# SPC1169 register map
File version: 2022071043481212
CPU: cm4 r1p0, little endian, no MPU, FPU, 4 interrupt priority bits
Registers are 32-bit, read-write, reset 0x0 unless marked. A register's access mark holds for its fields unless they carry their own. Offsets are from the block's base; [hi:lo] are bit positions; {n}, {i} and the like mark numbered series; 'fields as' and 'values as' point back to an identical list.

## PWM0 (part 1 of 2)
Base 0x40002000
Same registers: PWM1 0x40002100, PWM2 0x40002200, PWM3 0x40002300
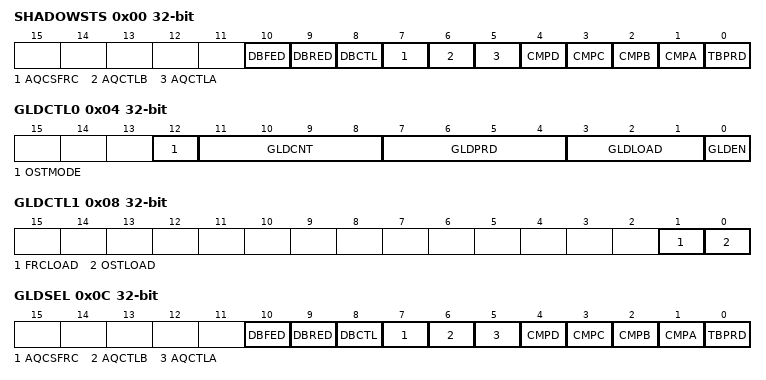
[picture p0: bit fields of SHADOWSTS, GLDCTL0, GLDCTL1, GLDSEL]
0x00 SHADOWSTS ro — Shadow Status Register
  [10] DBFED — DBFED shadow status
    0=EMPTY (A load from DBFED to DBFEDA clears this bit); 1=FULL (Write to DBFED set this bit and overwrite current value in DBFED)
  [9] DBRED — DBRED shadow status
    0=EMPTY (A load from DBRED to DBREDA clears this bit); 1=FULL (Write to DBRED set this bit and overwrite current value in DBRED)
  [8] DBCTL — DBCTL shadow status
    0=EMPTY (A load from DBCTL to DBCTLA clears this bit); 1=FULL (Write to DBCTL set this bit and overwrite current value in DBCTL)
  [7] AQCSFRC — AQCSFRC shadow status
    0=EMPTY (A load from AQCSFRC to AQCSFRCA clears this bit); 1=FULL (Write to AQCSFRC set this bit and overwrite current value in AQCSFRC)
  [6] AQCTLB — AQCTLB shadow status
    0=EMPTY (A load from AQCTLB to AQCTLBA clears this bit); 1=FULL (Write to AQCTLB set this bit and overwrite current value in AQCTLB)
  [5] AQCTLA — AQCTLA shadow status
    0=EMPTY (A load from AQCTLA to AQCTLAA clears this bit); 1=FULL (Write to AQCTLA set this bit and overwrite current value in AQCTLA)
  [4] CMPD — CMPD shadow status
    0=EMPTY (A load from CMPD to CMPDA clears this bit); 1=FULL (Write to CMPD set this bit and overwrite current value in CMPD)
  [3] CMPC — CMPC shadow status
    0=EMPTY (A load from CMPC to CMPCA clears this bit); 1=FULL (Write to CMPC set this bit and overwrite current value in CMPC)
  [2] CMPB — CMPB shadow status
    0=EMPTY (A load from CMPB to CMPBA clears this bit); 1=FULL (Write to CMPB set this bit and overwrite current value in CMPB)
  [1] CMPA — CMPA shadow status
    0=EMPTY (A load from CMPA to CMPAA clears this bit); 1=FULL (Write to CMPA set this bit and overwrite current value in CMPA)
  [0] TBPRD — TBPRD shadow status
    0=EMPTY (A load from TBPRD to TBPRDA clears this bit); 1=FULL (Write to TBPRD set this bit and overwrite current value in TBPRD)
0x04 GLDCTL0 — Global Shadow to Active Load Control Register 0
  [12] OSTMODE — One-shot global load mode
    0=CONTINUOUS_MODE (Global strobe is continuously controlled by GLDPRD and GLDCNT); 1=ONE_SHOT_MODE (Global strobe is blocked until GLDCTL1[OSTLOAD] is written with 1)
  [11:8] GLDCNT ro — Global shadow to active load strobe counter. It indicates how many selected global load events have occurred
  [7:4] GLDPRD — Global shadow to active load strobe period. No global load pulse will be generated if GLDPRD=0. Otherwise, the global load pulse is generated when new event comes upon GLDCNT=GLDPRD-1. In other words, the load pulse is generated every GLDPRD events. It has no effect if OSTMODE=1
  [3:1] GLDLOAD — Global shadow to active load mode
    0=LOAD_ON_ZERO (Load from shadow to active on TBCNT=0); 1=LOAD_ON_PERIOD (Load from shadow to active on TBCNT=TBPRD); 2=LOAD_ON_ZERO_PERIOD (Load from shadow to active on TBCNT=0 or TBCNT=TBPRD); 3=LOAD_ON_SYNC (Load from shadow to active on SYNC event); 4=LOAD_ON_SYNC_ZERO (Load from shadow to active on SYNC event or TBCNT=0); 5=LOAD_ON_SYNC_PERIOD (Load from shadow to active on SYNC event or TBCNT=TBPRD); 6=LOAD_ON_SYNC_ZERO_PERIOD (Load from shadow to active on SYNC event, TBCNT=0 or TBCNT=TBPRD); 7=LOAD_ON_FORCE (Load from shadow to active on software by writing 1 to GLDCTL1[FRCLOAD])
  [0] GLDEN — Global shadow to active load enable
    0=DISABLE (Shadow to active load is defined per register regardless of GLDSEL. i.e. CMPA load is always controlled by CMPCTL[CMPALOAD]); 1=ENABLE (Shadow to active load is globally controlled)
0x08 GLDCTL1 — Global Shadow to Active Load Control Register 1
  [1] FRCLOAD — Global force shadow to active load
    0=NO_EFFECT (Write 0 has no effect and always reads back 0); 1=FORCE (Write 1 generates global load event to the event counter)
  [0] OSTLOAD — Start the one-shot load pending
    0=NO_EFFECT (Write 0 has no effect. Read 0 indicates there is no pending one-shot load); 1=PENDING (Write 1 initialize a one-shot load pending. Upon event defined by GLDCTL[GLDLOAD], the global load happens and this bit is self-cleared to 0.)
0x0C GLDSEL — Global Shadow to Active Load Select Register
  [10] DBFED — DBFED global shadow to active load select
    0=LOCAL (Shadow to active load is controlled by DBCTL[DBFEDLOAD]); 1=GLOBAL (Shadow to active load is controlled by GLDCTL)
  [9] DBRED — DBRED global shadow to active load select
    0=LOCAL (Shadow to active load is controlled by DBCTL[DBREDLOAD]); 1=GLOBAL (Shadow to active load is controlled by GLDCTL)
  [8] DBCTL — DBCTL global shadow to active load select
    0=LOCAL (Shadow to active load is controlled by DBCTL[DBCTLLOAD]); 1=GLOBAL (Shadow to active load is controlled by GLDCTL)
  [7] AQCSFRC — AQCSFRC global shadow to active load select
    0=LOCAL (Shadow to active load is controlled by AQCTL[AQCSFRCLOAD]); 1=GLOBAL (Shadow to active load is controlled by GLDCTL)
  [6] AQCTLB — AQCTLB global shadow to active load select
    0=LOCAL (Shadow to active load is controlled by AQCTL[AQCTLBLOAD]); 1=GLOBAL (Shadow to active load is controlled by GLDCTL)
  [5] AQCTLA — AQCTLA global shadow to active load select
    0=LOCAL (Shadow to active load is controlled by AQCTL[AQCTLALOAD]); 1=GLOBAL (Shadow to active load is controlled by GLDCTL)
  [4] CMPD — CMPD global shadow to active load select
    0=LOCAL (Shadow to active load is controlled by CMPCTL[CMPDLOAD]); 1=GLOBAL (Shadow to active load is controlled by GLDCTL)
  [3] CMPC — CMPC global shadow to active load select
    0=LOCAL (Shadow to active load is controlled by CMPCTL[CMPCLOAD]); 1=GLOBAL (Shadow to active load is controlled by GLDCTL)
  [2] CMPB — CMPB global shadow to active load select
    0=LOCAL (Shadow to active load is controlled by CMPCTL[CMPBLOAD]); 1=GLOBAL (Shadow to active load is controlled by GLDCTL)
  [1] CMPA — CMPA global shadow to active load select
    0=LOCAL (Shadow to active load is controlled by CMPCTL[CMPALOAD]); 1=GLOBAL (Shadow to active load is controlled by GLDCTL)
  [0] TBPRD — TBPRD global shadow to active load select
    0=LOCAL (Shadow to active load is controlled by TBCTL[TBPRDLOAD]); 1=GLOBAL (Shadow to active load is controlled by GLDCTL)
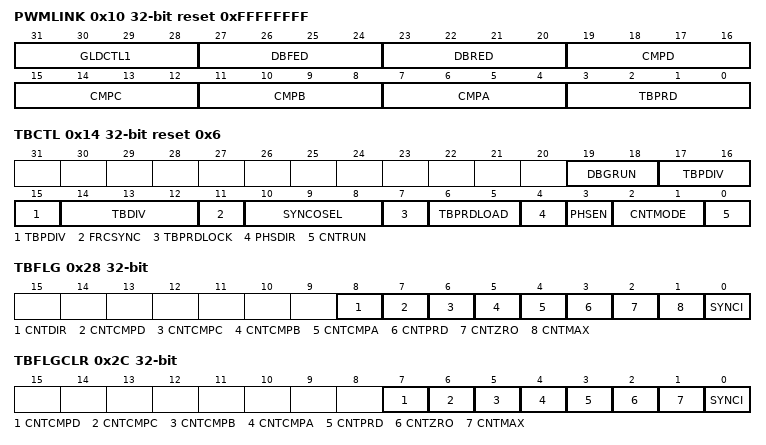
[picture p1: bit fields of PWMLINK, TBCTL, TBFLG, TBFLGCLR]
0x10 PWMLINK reset 0xFFFFFFFF — PWM Link Control Register
  [all] fields
    {v}=LINK_PWM{v} (Select PWM{v}) (v=0..3); 15=LINK_NONE (No PWM selected)
  [31:28] GLDCTL1 — Write to the GLDCTL1 of PWM selected by PWMLINK[GLDCTL1] results in simultaneous write to GLDCTL1 of current PWM module
  [27:24] DBFED — Write to the DBFED of PWM selected by PWMLINK[DBFED] results in simultaneous write to DBFED of current PWM module
  [23:20] DBRED — Write to the DBRED of PWM selected by PWMLINK[DBRED] results in simultaneous write to DBRED of current PWM module
  [19:16] CMPD — Write to the CMPD of PWM selected by PWMLINK[CMPD] results in simultaneous write to CMPD of current PWM module
  [15:12] CMPC — Write to the CMPC of PWM selected by PWMLINK[CMPC] results in simultaneous write to CMPC of current PWM module
  [11:8] CMPB — Write to the CMPB of PWM selected by PWMLINK[CMPB] results in simultaneous write to CMPB of current PWM module
  [7:4] CMPA — Write to the CMPA of PWM selected by PWMLINK[CMPA] results in simultaneous write to CMPA of current PWM module
  [3:0] TBPRD — Write to the TBPRD of PWM selected by PWMLINK[TBPRD] results in simultaneous write to TBPRD of current PWM module
0x14 TBCTL reset 0x6 — Time-Base Control Register
  [19:18] DBGRUN — PWM counter behaviour when CPU is halted . Note: Debug operation and CPU fault exceptions both can cause CPU halted.
    0=STOP_AFTER_COUNTING (Stop after the next time-base counter increment or decrement); 1=STOP_AFTER_CYCLE (Stop when TBCNT completes a whole cycle (TBCNT=TBPRD for up-count mode and TBCNT=0 for other modes)); 2=KEEP_RUN (Counter keep running when CPU is halted)
  [17:15] TBPDIV — TBCLK pre-dividing ratio from PWM clock input. Overall dividing ratio is 2^TBPDIV * (TBDIV+1)
    0=/1 (default on reset); 1=2; 2=4; 3=8; 4=16; 5=32; 6=64; 7=128
  [14:12] TBDIV — TBCLK dividing ratio from pre-divider output. Overall dividing ratio is 2^TBPDIV * (TBDIV+1)
    0=/1 (default on reset); {v}={v+1} (v=1..7)
  [11] FRCSYNC — Software forced synchronization. This event is ORed with SYNCI input and is valid only when SYNCOSEL=000
    0=NO_EFFECT (Write 0 has no effect and always reads back 0); 1=FORCE (Write 1 forces a one-time synchronization pulse. This bit is self-cleared to 0 and not affected by PWMREGKEY protection)
  [10:8] SYNCOSEL — Synchronization output select
    0=SYNCI_AND_FRCSYNC (SYNCI and the software forced sync); 1=TBCNT_EQU_ZERO (TBCNT=0 event); 2=TBCNT_EQU_TBPRD (TBCNT=TBPRD event); 3=TBCNT_EQU_CMPA (TBCNT=CMPA event); 4=TBCNT_EQU_CMPB (TBCNT=CMPB event); 5=TBCNT_EQU_CMPC (TBCNT=CMPC event); 6=TBCNT_EQU_CMPD (TBCNT=CMPD event); 7=DISABLE (Disable SYNCO)
  [7] TBPRDLOCK — TBPRD active value lock
    0=UNLOCK (Active value in TBPRDA is updated according to TBCTL[TBPRDLOAD]); 1=LOCK (Active value in TBPRDA will not change)
  [6:5] TBPRDLOAD — TBPRD active value load mode. It has no effect when TBCTL[TBPRDLOCK]=1
    0=LOAD_ON_ZERO (Load TBPRD into TBPRDA on TBCNT=0); 1=LOAD_ON_SYNC (Load TBPRD into TBPRDA on SYNC event); 2=LOAD_ON_SYNC_ZERO (Load TBPRD into TBPRDA on SYNC event or TBCNT=0); 3=LOAD_IMMEDIATE (Write TBPRD will immediately change the active value in TBPRDA)
  [4] PHSDIR — Phase direction. It is valid only when TBCNT is in up-down-count mode (CNTMODE=10)
    0=COUNT_DOWN_AFTER_SYNC (Count down after synchronization event); 1=COUNT_UP_AFTER_SYNC (Count up after synchronization event)
  [3] PHSEN — Phase register enable
    0=DISABLE (Do not load time-base counter (TBCNT) from time-base phase register (TBPHS)); 1=ENABLE (Load TBCNT from TBPHS when synchronization event occurs (SYNCI input, software synchronization or digital compare sync event))
  [2:1] CNTMODE — Counter mode
    0=COUNT_DOWN (Down-count); 1=COUNT_UP (Up-count); 2=COUNT_UP_DOWN (Up-down-count); 3=COUNT_FREEZE (Stop and freeze (default on reset))
  [0] CNTRUN — Counter run/stop control
    0=COUNT_STOP (Counter stop); 1=COUNT_RUN (Counter free-running)
0x18 TBPRD — Time-Base Period Register
  [15:0] VAL — Time-base counter period
0x1C TBPRDA ro — Time-Base Period Active Register
  [15:0] VAL — Time-base counter active period. When TBCTL[PRDLOAD]=0x3, write to TBPRD directly affects this register. Otherwise, the value is loaded from TBPRD upon the events defined in TBCTL[PRDLOAD].
0x20 TBPHS — Time-Base Phase Register
  [15:0] VAL — Time-base counter phase when synchronization event occurs. TBCTL[PHSEN]=0: The synchronization event is ignored and TBCNT keeps its value. TBCTL[PHSEN]=1: Time-base counter (TBCNT) will be loaded with TBPHS when synchronization event occurs.
0x24 TBCNT — Time-Base Counter Register
  [15:0] VAL — Current value of the time-base counter
0x28 TBFLG ro — Time-Base Status Register
  [8] CNTDIR — Time-base counter direction status
    0=COUNTING_DOWN (Time-base counter is currently counting down); 1=COUNTING_UP (Time-base counter is currently counting up)
  [7] CNTCMPD — Time-base counter reaching CMPD latched status
    0=NOT_REACHED (TBCNT never reaches CMPD); 1=REACHED (TBCNT reached CMPD)
  [6] CNTCMPC — Time-base counter reaching CMPC latched status
    0=NOT_REACHED (TBCNT never reaches CMPC); 1=REACHED (TBCNT reached CMPC)
  [5] CNTCMPB — Time-base counter reaching CMPB latched status
    0=NOT_REACHED (TBCNT never reaches CMPB); 1=REACHED (TBCNT reached CMPB)
  [4] CNTCMPA — Time-base counter reaching CMPA latched status
    0=NOT_REACHED (TBCNTnever reaches CMPA); 1=REACHED (TBCNT reached CMPA)
  [3] CNTPRD — Time-base counter reaching period latched status
    0=NOT_REACHED (TBCNT never reaches TBPRD); 1=REACHED (TBCNT reached TBPRD)
  [2] CNTZRO — Time-base counter reaching zero latched status
    0=NOT_REACHED (TBCNT never reaches 0x0); 1=REACHED (TBCNT reached 0x0)
  [1] CNTMAX — Time-base counter reaching max latched status
    0=NOT_REACHED (TBCNT never reaches 0xFFFF); 1=REACHED (TBCNT reached 0xFFFF)
  [0] SYNCI — Input synchronization latched status
    0=NO_EVENT (No input synchronization event has occurred); 1=EVENT_OCCUR (An input synchronization event has occurred)
0x2C TBFLGCLR — Time-Base Status Clear Register
  [7] CNTCMPD — Time-base counter reaching CMPD latched status clear
    0=NO_EFFECT (Write 0 has no effect and always reads back 0); 1=CLEAR (Write 1 cleares the TZFLG.CNTCMPD. This bit is self-cleared to 0)
  [6] CNTCMPC — Time-base counter reaching CMPC latched status clear
    0=NO_EFFECT (Write 0 has no effect and always reads back 0); 1=CLEAR (Write 1 cleares the TZFLG.CNTCMPC. This bit is self-cleared to 0)
  [5] CNTCMPB — Time-base counter reaching CMPB latched status clear
    0=NO_EFFECT (Write 0 has no effect and always reads back 0); 1=CLEAR (Write 1 cleares the TZFLG.CNTCMPB. This bit is self-cleared to 0)
  [4] CNTCMPA — Time-base counter reaching CMPA latched status clear
    0=NO_EFFECT (Write 0 has no effect and always reads back 0); 1=CLEAR (Write 1 cleares the TZFLG.CNTCMPA. This bit is self-cleared to 0)
  [3] CNTPRD — Time-base counter reaching period latched status clear
    0=NO_EFFECT (Write 0 has no effect and always reads back 0); 1=CLEAR (Write 1 cleares the TZFLG.CNTPRD. This bit is self-cleared to 0)
  [2] CNTZRO — Time-base counter reaching zero latched status clear
    0=NO_EFFECT (Write 0 has no effect and always reads back 0); 1=CLEAR (Write 1 cleares the TZFLG.CNTZRO. This bit is self-cleared to 0)
  [1] CNTMAX — Time-base counter reaching max latched status clear
    0=NO_EFFECT (Write 0 has no effect and always reads back 0); 1=CLEAR (Write 1 cleares the TZFLG.CNTMAX. This bit is self-cleared to 0)
  [0] SYNCI — Input synchronization latched status clear
    0=NO_EFFECT (Write 0 has no effect and always reads back 0); 1=CLEAR (Write 1 cleares the TZFLG.SYNCI. This bit is self-cleared to 0)
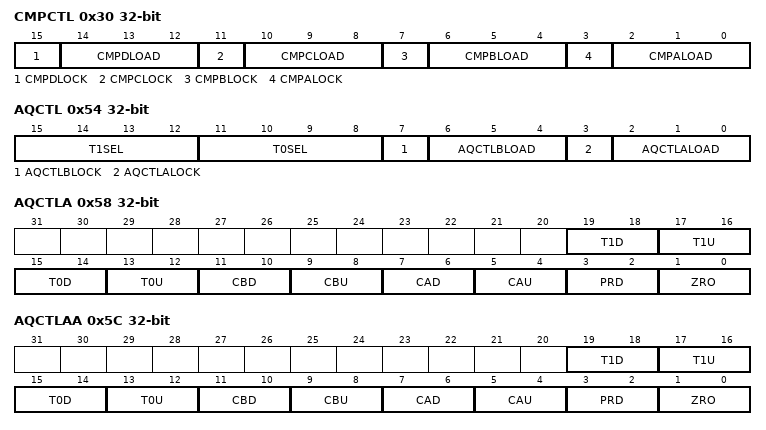
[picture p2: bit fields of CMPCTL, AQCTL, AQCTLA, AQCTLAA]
0x30 CMPCTL — Counter-Compare Control Register
  [15] CMPDLOCK — CMPD active value lock
    0=UNLOCK (Active value in CMPDA is updated according to CMPCTL.CMPDLOAD); 1=LOCK (Active value in CMPDA will not change)
  [14:12] CMPDLOAD — CMPD active value load mode. It has no effect when CMPCTL[CMPDLOCK]=1
    0=LOAD_ON_ZERO (Load CMPD into CMPDA on TBCNT=0); 1=LOAD_ON_PERIOD (Load CMPD into CMPDA on TBCNT=TBPRD); 2=LOAD_ON_ZERO_PERIOD (Load CMPD into CMPDA on TBCNT=0 or TBCNT=TBPRD); 3=LOAD_ON_SYNC (Load CMPD into CMPDA on SYNC event); 4=LOAD_ON_SYNC_ZERO (Load CMPD into CMPDA on SYNC event or TBCNT=0); 5=LOAD_ON_SYNC_PERIOD (Load CMPD into CMPDA on SYNC event or TBCNT=TBPRD); 6=LOAD_ON_SYNC_ZERO_PERIOD (Load CMPD into CMPDA on SYNC event, TBCNT=0 or TBCNT=TBPRD); 7=LOAD_IMMEDIATE (Write CMPD will immediately change the active value in CMPDA)
  [11] CMPCLOCK — CMPC active value lock
    0=UNLOCK (Active value in CMPCA is updated according to CMPCTL.CMPCLOAD); 1=LOCK (Active value in CMPCA will not change)
  [10:8] CMPCLOAD — CMPC active value load mode. It has no effect when CMPCTL[CMPCLOCK]=1
    0=LOAD_ON_ZERO (Load CMPC into CMPCA on TBCNT=0); 1=LOAD_ON_PERIOD (Load CMPC into CMPCA on TBCNT=TBPRD); 2=LOAD_ON_ZERO_PERIOD (Load CMPC into CMPCA on TBCNT=0 or TBCNT=TBPRD); 3=LOAD_ON_SYNC (Load CMPC into CMPCA on SYNC event); 4=LOAD_ON_SYNC_ZERO (Load CMPC into CMPCA on SYNC event or TBCNT=0); 5=LOAD_ON_SYNC_PERIOD (Load CMPC into CMPCA on SYNC event or TBCNT=TBPRD); 6=LOAD_ON_SYNC_ZERO_PERIOD (Load CMPC into CMPCA on SYNC event, TBCNT=0 or TBCNT=TBPRD); 7=LOAD_IMMEDIATE (Write CMPC will immediately change the active value in CMPCA)
  [7] CMPBLOCK — CMPB active value lock
    0=UNLOCK (Active value in CMPBA is updated according to CMPBTL.CMPBLOAD); 1=LOCK (Active value in CMPBA will not change)
  [6:4] CMPBLOAD — CMPB active value load mode. It has no effect when CMPBTL[CMPBLOCK]=1
    0=LOAD_ON_ZERO (Load CMPB into CMPBA on TBCNT=0); 1=LOAD_ON_PERIOD (Load CMPB into CMPBA on TBCNT=TBPRD); 2=LOAD_ON_ZERO_PERIOD (Load CMPB into CMPBA on TBCNT=0 or TBCNT=TBPRD); 3=LOAD_ON_SYNC (Load CMPB into CMPBA on SYNC event); 4=LOAD_ON_SYNC_ZERO (Load CMPB into CMPBA on SYNC event or TBCNT=0); 5=LOAD_ON_SYNC_PERIOD (Load CMPB into CMPBA on SYNC event or TBCNT=TBPRD); 6=LOAD_ON_SYNC_ZERO_PERIOD (Load CMPB into CMPBA on SYNC event, TBCNT=0 or TBCNT=TBPRD); 7=LOAD_IMMEDIATE (Write CMPB will immediately change the active value in CMPBA)
  [3] CMPALOCK — CMPA active value lock
    0=UNLOCK (Active value in CMPAA is updated according to CMPATL.CMPALOAD); 1=LOCK (Active value in CMPAA will not change)
  [2:0] CMPALOAD — CMPA active value load mode. It has no effect when CMPATL[CMPALOCK]=1
    0=LOAD_ON_ZERO (Load CMPA into CMPAA on TBCNT=0); 1=LOAD_ON_PERIOD (Load CMPA into CMPAA on TBCNT=TBPRD); 2=LOAD_ON_ZERO_PERIOD (Load CMPA into CMPAA on TBCNT=0 or TBCNT=TBPRD); 3=LOAD_ON_SYNC (Load CMPA into CMPAA on SYNC event); 4=LOAD_ON_SYNC_ZERO (Load CMPA into CMPAA on SYNC event or TBCNT=0); 5=LOAD_ON_SYNC_PERIOD (Load CMPA into CMPAA on SYNC event or TBCNT=TBPRD); 6=LOAD_ON_SYNC_ZERO_PERIOD (Load CMPA into CMPAA on SYNC event, TBCNT=0 or TBCNT=TBPRD); 7=LOAD_IMMEDIATE (Write CMPA will immediately change the active value in CMPAA)
0x34 CMPA — Counter-Compare A Threshold Register
  [15:0] VAL — Comparator A threshold
0x38 CMPAA ro — Counter-Compare A Threshold Active Register
  [15:0] VAL — Comparator A threshold active value. A TBCNT=CMPA event will be generated while TBCNT is equal to the threshold value
0x3C CMPB — Counter-Compare B Threshold Register
  [15:0] VAL — Comparator B threshold
0x40 CMPBA ro — Counter-Compare B Threshold Active Register
  [15:0] VAL — Comparator B threshold active value. A TBCNT=CMPB event will be generated while TBCNT is equal to the threshold value
0x44 CMPC — Counter-Compare C Threshold Register
  [15:0] VAL — Comparator C threshold
0x48 CMPCA ro — Counter-Compare C Threshold Active Register
  [15:0] VAL — Comparator C threshold active value. A TBCNT=CMPC event will be generated while TBCNT is equal to the threshold value
0x4C CMPD — Counter-Compare D Threshold Register
  [15:0] VAL — Comparator D threshold
0x50 CMPDA ro — Counter-Compare D Threshold Active Register
  [15:0] VAL — Comparator D threshold active value. A TBCNT=CMPD event will be generated while TBCNT is equal to the threshold value
0x54 AQCTL — Action-Qualifier Control Register
  [15:12] T1SEL — T1 event source select
    0=DCAEVT0; 1=DCAEVT1; 2=DCBEVT0; 3=DCBEVT1; {v}=TZ{v-4} (v=4..8); 9=SYNCI
  [11:8] T0SEL — T0 event source select
    values as T1SEL
  [7] AQCTLBLOCK — AQCTLB active value lock
    0=UNLOCK (Active value in AQCTLBA is updated according to AQCTL.AQCTLBLOAD); 1=LOCK (Active value in AQCTLBA will not change)
  [6:4] AQCTLBLOAD — AQCTLB active value load mode. It has no effect when AQCTL[AQCTLBLOCK]=1
    0=LOAD_ON_ZERO (Load AQCTLB into AQCTLBA on TBCNT=0); 1=LOAD_ON_PERIOD (Load AQCTLB into AQCTLBA on TBCNT=TBPRD); 2=LOAD_ON_ZERO_PERIOD (Load AQCTLB into AQCTLBA on TBCNT=0 or TBCNT=TBPRD); 3=LOAD_ON_SYNC (Load AQCTLB into AQCTLBA on SYNC event); 4=LOAD_ON_SYNC_ZERO (Load AQCTLB into AQCTLBA on SYNC event or TBCNT=0); 5=LOAD_ON_SYNC_PERIOD (Load AQCTLB into AQCTLBA on SYNC event or TBCNT=TBPRD); 6=LOAD_ON_SYNC_ZERO_PERIOD (Load AQCTLB into AQCTLBA on SYNC event, TBCNT=0 or TBCNT=TBPRD); 7=LOAD_IMMEDIATE (Write AQCTLB immediately change the active value in AQCTLBA)
  [3] AQCTLALOCK — AQCTLA active value lock
    0=UNLOCK (Active value in AQCTLAA is updated according to AQCTL[AQCTLALOAD]); 1=LOCK (Active value in AQCTLAA will not change)
  [2:0] AQCTLALOAD — AQCTLA active value load mode. It has no effect when AQCTL[AQCTLALOCK]=1
    0=LOAD_ON_ZERO (Load AQCTLA into AQCTLAA on TBCNT=0); 1=LOAD_ON_PERIOD (Load AQCTLA into AQCTLAA on TBCNT=TBPRD); 2=LOAD_ON_ZERO_PERIOD (Load AQCTLA into AQCTLAA on TBCNT=0 or TBCNT=TBPRD); 3=LOAD_ON_SYNC (Load AQCTLA into AQCTLAA on SYNC event); 4=LOAD_ON_SYNC_ZERO (Load AQCTLA into AQCTLAA on SYNC event or TBCNT=0); 5=LOAD_ON_SYNC_PERIOD (Load AQCTLA into AQCTLAA on SYNC event or TBCNT=TBPRD); 6=LOAD_ON_SYNC_ZERO_PERIOD (Load AQCTLA into AQCTLAA on SYNC event, TBCNT=0 or TBCNT=TBPRD); 7=LOAD_IMMEDIATE (Write AQCTLA immediately change the active value in AQCTLAA)
0x58 AQCTLA — Action-Qualifier Output A Control Register
  [all] fields
    0=DO_NOTHING (Do nothing (action disabled)); 1=SET_LOW (Clear (force PWM output A to low)); 2=SET_HIGH (Set (force PWM output A to high)); 3=TOGGLE (Toggle (invert current PWM output A status))
  [19:18] T1D — Action on output A when T1 event and TBCNT is counting down
  [17:16] T1U — Action on output A when T1 event and TBCNT is counting up
  [15:14] T0D — Action on output A when T0 event and TBCNT is counting down
  [13:12] T0U — Action on output A when T0 event and TBCNT is counting up
  [11:10] CBD — Action on output A when TBCNT=CMPB and TBCNT is counting down
  [9:8] CBU — Action on output A when TBCNT=CMPB and TBCNT is counting up
  [7:6] CAD — Action on output A when TBCNT=CMPA and TBCNT is counting down
  [5:4] CAU — Action on output A when TBCNT=CMPA and TBCNT is counting up
  [3:2] PRD — Action on output A when TBCNT=TBPRD
  [1:0] ZRO — Action on output A when TBCNT=Zero
0x5C AQCTLAA ro — Action-Qualifier Output A Control Active Register
  fields as AQCTLA
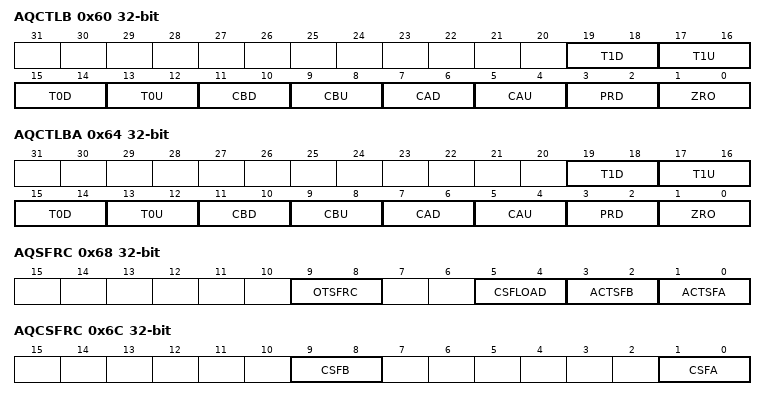
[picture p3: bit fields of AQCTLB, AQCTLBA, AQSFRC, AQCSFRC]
0x60 AQCTLB — Action-Qualifier Output B Control Register
  [all] fields
    0=DO_NOTHING (Do nothing (action disabled)); 1=SET_LOW (Clear (force PWM output B to low)); 2=SET_HIGH (Set (force PWM output B to high)); 3=TOGGLE (Toggle (invert current PWM output B status))
  [19:18] T1D — Action on output B when T1 event and TBCNT is counting down
  [17:16] T1U — Action on output B when T1 event and TBCNT is counting up
  [15:14] T0D — Action on output B when T0 event and TBCNT is counting down
  [13:12] T0U — Action on output B when T0 event and TBCNT is counting up
  [11:10] CBD — Action on output B when TBCNT=CMPA and TBCNT is counting down
  [9:8] CBU — Action on output B when TBCNT=CMPB and TBCNT is counting up
  [7:6] CAD — Action on output B when TBCNT=CMPA and TBCNT is counting down
  [5:4] CAU — Action on output B when TBCNT=CMPA and TBCNT is counting up
  [3:2] PRD — Action on output B when TBCNT=TBPRD
  [1:0] ZRO — Action on output B when TBCNT=Zero
0x64 AQCTLBA ro — Action-Qualifier Output B Control Active Register
  fields as AQCTLB
0x68 AQSFRC — Action-Qualifier Software Force Register
  [9:8] OTSFRC — One-time software forced event on output
    0=NO_EFFECT (Write a 0 has no effect and always reads back 0); 1=FORCE_A; 2=FORCE_B; 3=FORCE_A_AND_B (Write a 1 initialize a one-cycle force pulse. This bit is self-cleared to 0)
  [5:4] CSFLOAD — Options to load continuous software force register (AQCSFRC) active value from shadow register
    0=LOAD_ON_ZERO (Load from AQCSFRC into AQCSFRCA on TBCNT=0); 1=LOAD_ON_PERIOD (Load from AQCSFRC into AQCSFRCA on TBCNT=TBPRD); 2=LOAD_ON_ZERO_PERIOD (Load from AQCSFRC into AQCSFRCA on TBCNT=Zero or TBCNT=TBPRD); 3=LOAD_IMMEDIATE (Write AQCSFRC immediately change the active value in AQCSFRCA)
  [3:2] ACTSFB — Action when one-time software force B is invoked
    0=DO_NOTHING (Do nothing (action disabled)); 1=SET_LOW (Clear (force PWM output B to low); 2=SET_HIGH (Set (force PWM output B to high); 3=TOGGLE (Toggle (invert current PWM AQ output B status))
  [1:0] ACTSFA — Action when one-time software force A is invoked
    0=DO_NOTHING (Do nothing (action disabled)); 1=SET_LOW (Clear (force PWM output A to low); 2=SET_HIGH (Set (force PWM output A to high); 3=TOGGLE (Toggle (invert current PWM AQ output A status))
0x6C AQCSFRC — Action-Qualifier Continuous Software Force Register
  [9:8] CSFB — Continuous software force on output B
    0=DISABLE (Forcing disabled); 1=FORCE_CONTINUOUS_LOW (Force a continuous low on output B); 2=FORCE_CONTINUOUS_HIGH (Force a continuous high on output B); 3=NO_EFFECT (Invalid option)
  [1:0] CSFA — Continuous software force on output A
    0=DISABLE (Forcing disabled); 1=FORCE_CONTINUOUS_LOW (Force a continuous low on output A); 2=FORCE_CONTINUOUS_HIGH (Force a continuous high on output A); 3=NO_EFFECT (Invalid option)
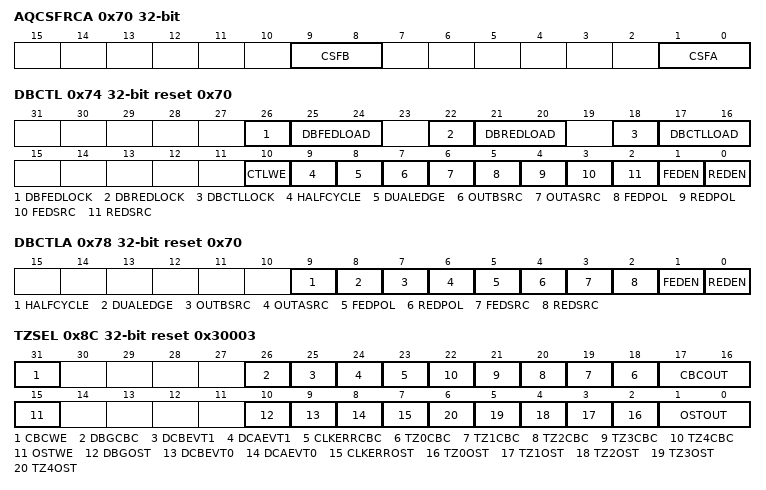
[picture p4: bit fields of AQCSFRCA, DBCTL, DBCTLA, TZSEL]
0x70 AQCSFRCA ro — Action-Qualifier Continuous Software Force Active Register
  fields as AQCSFRC
0x74 DBCTL reset 0x70 — Dead-Band Generator Control Register
  [26] DBFEDLOCK — DBFED active value lock
    0=UNLOCK (Active value in DBFEDA is updated according to DBCTL[DBFEDLOAD]); 1=LOCK (Active value in DBFEDA will not change)
  [25:24] DBFEDLOAD — DBFED active value load mode. It has no effect when DBCTL[DBFEDLOCK]=1
    0=LOAD_ON_ZERO (Load DBFED into DBFEDA on TBCNT=0); 1=LOAD_ON_PERIOD (Load DBFED into DBFEDA on TBCNT=TBPRD); 2=LOAD_ON_ZERO_PERIOD (Load DBFED into DBFEDA on TBCNT=0 or TBCNT=TBPRD); 3=LOAD_IMMEDIATE (Write DBFED immediately change the active value in DBFEDA)
  [22] DBREDLOCK — DBRED active value lock
    0=UNLOCK (Active value in DBREDA is updated according to DBCTL[DBREDLOAD]); 1=LOCK (Active value in DBREDA will not change)
  [21:20] DBREDLOAD — DBRED active value load mode. It has no effect when DBCTL[DBFEDLOCK]=1
    0=LOAD_ON_ZERO (Load DBRED into DBREDA on TBCNT=0); 1=LOAD_ON_PERIOD (Load DBRED into DBREDA on TBCNT=TBPRD); 2=LOAD_ON_ZERO_PERIOD (Load DBRED into DBREDA on TBCNT=0 or TBCNT=TBPRD); 3=LOAD_IMMEDIATE (Write DBRED will immediately change the active value in DBREDA)
  [18] DBCTLLOCK — DBCTL[9:0] active value lock
    0=UNLOCK (Active value in DBCTLA is updated according to DBCTL[DBCTLLOAD]); 1=LOCK (Active value in DBCTLA will not change)
  [17:16] DBCTLLOAD — DBCTL[9:0] active value load mode. It has no effect when DBCTL[DBCTLLOCK]=1
    0=LOAD_ON_ZERO (Load DBCTL[9:0] into DBCTLA on TBCNT=0); 1=LOAD_ON_PERIOD (Load DBCTL[9:0] into DBCTLA on TBCNT=TBPRD); 2=LOAD_ON_ZERO_PERIOD (Load DBCTL[9:0] into DBCTLA on TBCNT=0 or TBCNT=TBPRD); 3=LOAD_IMMEDIATE (Write DBCTL[9:0] will immediately change the active value in DBCTLA)
  [10] CTLWE — 10 LSBs of the dead-band control write enable. In order to write the 10 LSBs, this bit need to be write 1 simultaneously
    0=NO_EFFECT (10 LSBs will not be written); 1=ENABLE (10 LSBs will be written)
  [9] HALFCYCLE — Half cycle clocking enable
    0=DISABLE (Full cycle clocking enabled. The dead-band counter is clocked at TBCLK.); 1=ENABLE (Half cycle clocking enabled. The dead-band counter is clocked at 2x TBCLK.)
  [8] DUALEDGE — Dual-edge delay mode
    0=DISABLE (Rising-edge delay and falling-edge delay are two separate paths); 1=ENABLE (Rising-edge delay path output serves as input for Falling-edge delay path)
  [7] OUTBSRC — Output B source
    0=FALLING_EDGE (Falling-edge delay path is selected as output B); 1=RISING_EDGE (Rising-edge delay path is selected as output B)
  [6] OUTASRC — Output A source
    0=FALLING_EDGE (Falling-edge delay path is selected as output A); 1=RISING_EDGE (Rising-edge delay path is selected as output A)
  [5] FEDPOL — Falling-edge delay output polarity
    0=ACTIVE_LOW (Falling-edge delay output is inverted to have active-low polarity); 1=ACTIVE_HIGH (Falling-edge delay output keeps the original active-high polarity)
  [4] REDPOL — Rising-edge delay output polarity
    0=ACTIVE_LOW (Rising-edge delay output is inverted to have active-low polarity); 1=ACTIVE_HIGH (Rising-edge delay output keeps the original active-high polarity)
  [3] FEDSRC — Falling-edge delay source
    0=FROM_A (Input A is the source for falling-edge delay); 1=FROM_B (Input B is the source for falling-edge delay)
  [2] REDSRC — Rising-edge delay source
    0=FROM_A (Input A is the source for rising-edge delay); 1=FROM_B (Input B is the source for rising-edge delay)
  [1] FEDEN — Falling-edge delay enable
    0=DISABLE (Falling-edge delay is bypassed and the input from action-qualifier goes to the submodule directly); 1=ENABLE (Falling-edge delay is enabled and applied at output B)
  [0] REDEN — Rising-edge delay enable
    0=DISABLE (Rising-edge delay is bypassed and the input from action-qualifier goes to the submodule directly); 1=ENABLE (Rising-edge delay is enabled and applied at output A)
0x78 DBCTLA ro reset 0x70 — Dead-Band Generator Control Active Register
  [9] HALFCYCLE — Half cycle clocking enable
    values as DBCTL.HALFCYCLE
  [8] DUALEDGE — Dual-edge delay mode
    values as DBCTL.DUALEDGE
  [7] OUTBSRC — Output B source
    values as DBCTL.OUTBSRC
  [6] OUTASRC — Output A source
    values as DBCTL.OUTASRC
  [5] FEDPOL — Falling-edge delay output polarity
    values as DBCTL.FEDPOL
  [4] REDPOL — Rising-edge delay output polarity
    values as DBCTL.REDPOL
  [3] FEDSRC — Falling-edge delay source
    values as DBCTL.FEDSRC
  [2] REDSRC — Rising-edge delay source
    values as DBCTL.REDSRC
  [1] FEDEN — Falling-edge delay enable
    values as DBCTL.FEDEN
  [0] REDEN — Rising-edge delay enable
    values as DBCTL.REDEN
0x7C DBRED — Dead-Band Generator Rising Edge Delay Register
  [15:0] VAL — Rising-edge delay
0x80 DBREDA ro — Dead-Band Generator Rising Edge Delay Active Register
  [15:0] VAL — Rising-edge delay
0x84 DBFED — Dead-Band Generator Falling Edge Delay Register
  [15:0] VAL — Falling-edge delay
0x88 DBFEDA ro — Dead-Band Generator Falling Edge Delay Active Register
  [15:0] VAL — Falling-edge delay
0x8C TZSEL reset 0x30003 — Trip-Zone Event Select Register
  [31] CBCWE — Cycle-by-cycle trip-zone event select control bits write enable
    0=NO_EFFECT (Write 0 has no effect and always reads back 0); 1=ENABLE (Write 1 enables concurrent write to 16 MSBs. This bit is self-cleared to 0)
  [26] DBGCBC — JTAG debug as cycle-by-cycle trip source (ORed)
    0=DISABLE; 1=ENABLE
  [25] DCBEVT1 — Digital compare B event 1 as a cycle-by-cycle trip source (ORed)
    0=DISABLE; 1=ENABLE
  [24] DCAEVT1 — Digital compare A event 1 as a cycle-by-cycle trip source (ORed)
    0=DISABLE; 1=ENABLE
  [23] CLKERRCBC — Clock error as a cycle-by-cycle trip source (ORed)
    0=DISABLE; 1=ENABLE
  [n+18] TZ{n}CBC (n=0..4) — TZ{n} as a cycle-by-cycle trip source (ORed)
    0=DISABLE; 1=ENABLE
  [17:16] CBCOUT — Cycle-by-cycle trip-zone output select
    0=DISABLE (Disable cycle-by-cycle trip-zone); 1=ASYNC (Select only the asynchronous path. i.e. The original event OR gate output); 2=LATCH (Select only the latched path); 3=ASYNC_OR_LATCH (Select both the asynchronous path and the latched path (ORed))
  [15] OSTWE — One-shot trip-zone event select control bits write enable
    0=NO_EFFECT (Write 0 has no effect and always reads back 0); 1=ENABLE (Write 1 enable concurrent write to 16 LSBs. This bit is self-cleared to 0)
  [10] DBGOST — JTAG debug as a one-shot trip source (ORed)
    0=DISABLE; 1=ENABLE
  [9] DCBEVT0 — Digital compare B event 0 as a one-shot trip source (ORed)
    0=DISABLE; 1=ENABLE
  [8] DCAEVT0 — Digital compare A event 0 as a one-shot trip source (ORed)
    0=DISABLE; 1=ENABLE
  [7] CLKERROST — Clock error as a one-shot trip source (ORed)
    0=DISABLE; 1=ENABLE
  [n+2] TZ{n}OST (n=0..4) — TZ{n} as a one-shot trip source (ORed)
    0=DISABLE; 1=ENABLE
  [1:0] OSTOUT — One-shot trip-zone output select
    0=DISABLE (Disable one-shot trip-zone); 1=ASYNC (Select only the asynchronous path. i.e. The original event OR gate output); 2=LATCH (Select only the latched path); 3=ASYNC_OR_LATCH (Select both the asynchronous path and the latched path (ORed))
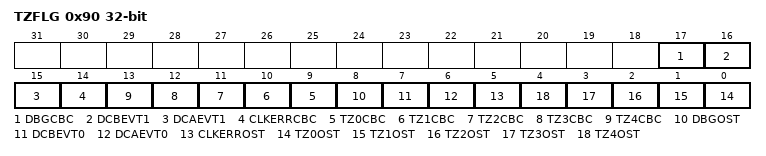
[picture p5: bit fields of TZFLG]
0x90 TZFLG ro — Trip-Zone Flag Register
  [all] fields
    0=NOT_OCCUR (No event has occurred); 1=OCCUR (Event occurred)
  [17] DBGCBC — Latched JTAG debug cycle-by-cycle trip event flag
  [16] DCBEVT1 — Latched digital compare B event 1 cycle-by-cycle trip flag
  [15] DCAEVT1 — Latched digital compare A event 1 cycle-by-cycle trip flag
  [14] CLKERRCBC — Latched clock error cycle-by-cycle trip event flag
  [n+9] TZ{n}CBC (n=0..4) — Latched TZ{n} cycle-by-cycle trip event flag
  [8] DBGOST — Latched JTAG debug one-shot trip event flag
  [7] DCBEVT0 — Latched digital compare B event 0 one-shot trip flag
  [6] DCAEVT0 — Latched digital compare A event 0 one-shot trip flag
  [5] CLKERROST — Latched clock error one-shot trip event flag
  [n] TZ{n}OST (n=0..4) — Latched TZ{n} one-shot trip event flag
